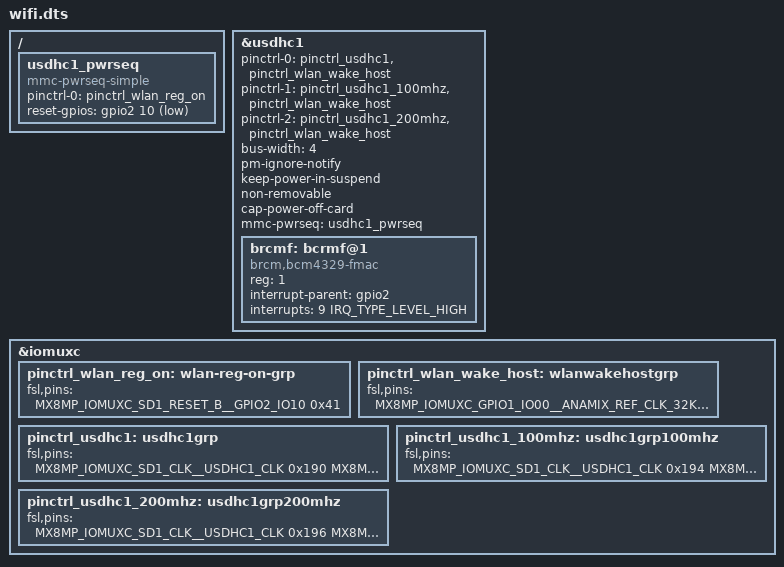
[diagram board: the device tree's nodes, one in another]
/{
	usdhc1_pwrseq: usdhc1_pwrseq {
		compatible = "mmc-pwrseq-simple";
		pinctrl-names = "default";
		pinctrl-0 = <&pinctrl_wlan_reg_on>;  
		reset-gpios = <&gpio2 10 GPIO_ACTIVE_LOW>;
  	};
};
&usdhc1 {
	#address-cells = <1>;
	#size-cells = <0>;
	pinctrl-names = "default", "state_100mhz", "state_200mhz";
	pinctrl-0 = <&pinctrl_usdhc1>, <&pinctrl_wlan_wake_host>;
	pinctrl-1 = <&pinctrl_usdhc1_100mhz>, <&pinctrl_wlan_wake_host>;
	pinctrl-2 = <&pinctrl_usdhc1_200mhz>, <&pinctrl_wlan_wake_host>;
	bus-width = <4>;
	pm-ignore-notify;
	keep-power-in-suspend;
	non-removable;
	cap-power-off-card;
	/delete-property/ vmmc-supply;
	mmc-pwrseq = <&usdhc1_pwrseq>;
	status = "okay";

	brcmf: bcrmf@1 {
		reg = <1>;
		compatible = "brcm,bcm4329-fmac";
		interrupt-parent = <&gpio2>;
		interrupts = <9 IRQ_TYPE_LEVEL_HIGH>; //wlan wake host
		interrupt-names = "host-wake";
	};
};


&iomuxc {

	//WL_REG_ON
	pinctrl_wlan_reg_on: wlan-reg-on-grp {
		fsl,pins = <
			MX8MP_IOMUXC_SD1_RESET_B__GPIO2_IO10     0x41
		>;
	};
	pinctrl_wlan_wake_host: wlanwakehostgrp {
		fsl,pins = <
			MX8MP_IOMUXC_GPIO1_IO00__ANAMIX_REF_CLK_32K      0x141
      			MX8MP_IOMUXC_SD1_DATA7__GPIO2_IO09                0x111 //WL_WAKE_HOST
		>;
	};
	pinctrl_usdhc1: usdhc1grp {
		fsl,pins = <
			MX8MP_IOMUXC_SD1_CLK__USDHC1_CLK	0x190
			MX8MP_IOMUXC_SD1_CMD__USDHC1_CMD	0x1d0
			MX8MP_IOMUXC_SD1_DATA0__USDHC1_DATA0	0x1d0
			MX8MP_IOMUXC_SD1_DATA1__USDHC1_DATA1	0x1d0
			MX8MP_IOMUXC_SD1_DATA2__USDHC1_DATA2	0x1d0
			MX8MP_IOMUXC_SD1_DATA3__USDHC1_DATA3	0x1d0
		>;
	};
	pinctrl_usdhc1_100mhz: usdhc1grp100mhz {
		fsl,pins = <
			MX8MP_IOMUXC_SD1_CLK__USDHC1_CLK         0x194
			MX8MP_IOMUXC_SD1_CMD__USDHC1_CMD         0x1d4
			MX8MP_IOMUXC_SD1_DATA0__USDHC1_DATA0     0x1d4
			MX8MP_IOMUXC_SD1_DATA1__USDHC1_DATA1     0x1d4
			MX8MP_IOMUXC_SD1_DATA2__USDHC1_DATA2     0x1d4
			MX8MP_IOMUXC_SD1_DATA3__USDHC1_DATA3     0x1d4
		>;
  	};

	pinctrl_usdhc1_200mhz: usdhc1grp200mhz {
		fsl,pins = <
			MX8MP_IOMUXC_SD1_CLK__USDHC1_CLK         0x196
			MX8MP_IOMUXC_SD1_CMD__USDHC1_CMD         0x1d6
			MX8MP_IOMUXC_SD1_DATA0__USDHC1_DATA0     0x1d6
			MX8MP_IOMUXC_SD1_DATA1__USDHC1_DATA1     0x1d6
			MX8MP_IOMUXC_SD1_DATA2__USDHC1_DATA2     0x1d6
			MX8MP_IOMUXC_SD1_DATA3__USDHC1_DATA3     0x1d6
		>;
	};
};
